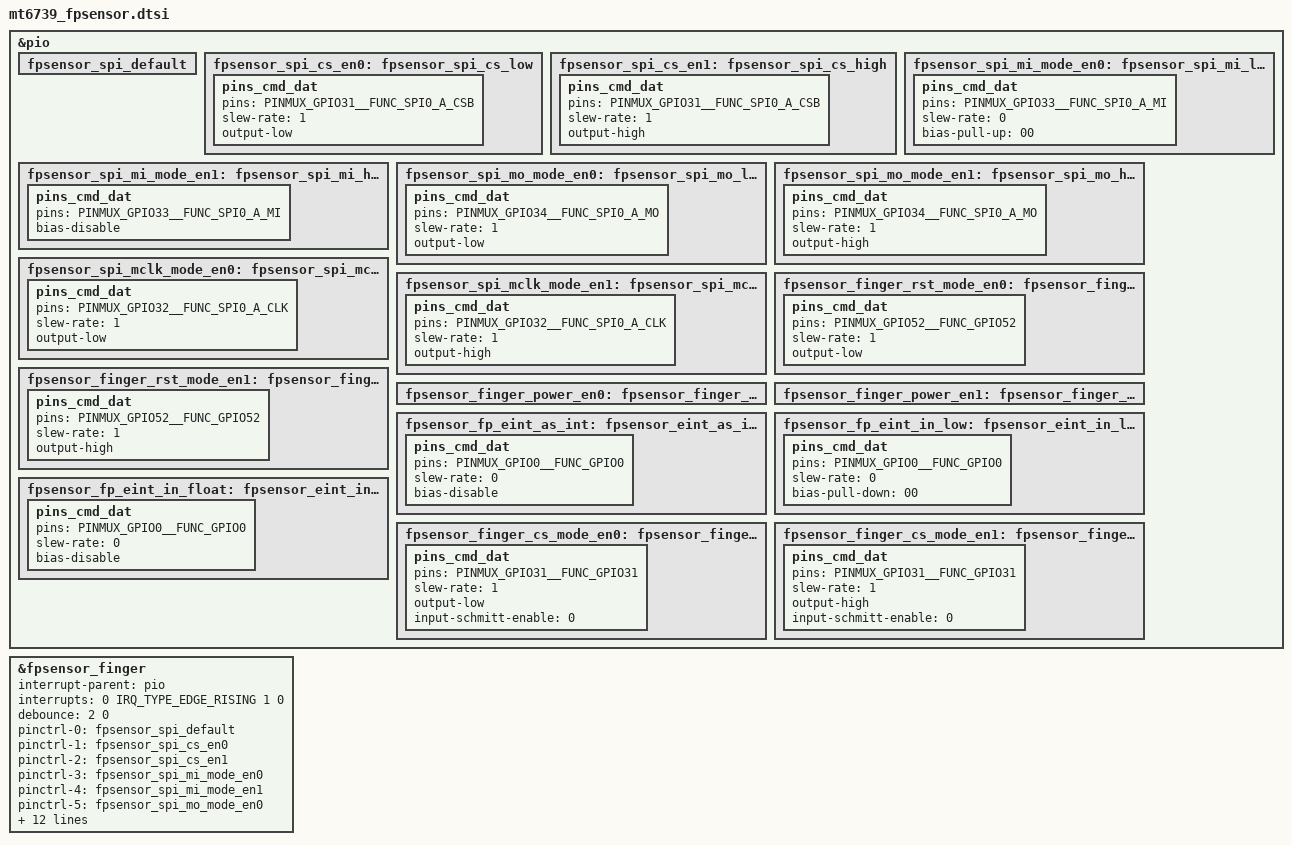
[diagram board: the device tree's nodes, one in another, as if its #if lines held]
#include <generated/autoconf.h>
//dts-v1

#ifdef CONFIG_MTK_DTBO_FEATURE
///plugin
#include <dt-bindings/clock/mt6739-clk.h>
#include <dt-bindings/mmc/mt6739-msdc.h>
#include <dt-bindings/pinctrl/mt6739-pinfunc.h>
#else
#include "mt6739.dts"
#endif

#include <dt-bindings/interrupt-controller/irq.h>
#include <dt-bindings/interrupt-controller/arm-gic.h>


/* FPSENSOR start */
&pio {

	fpsensor_spi_default: fpsensor_spi_default {
	};

	fpsensor_spi_cs_en0: fpsensor_spi_cs_low {
		pins_cmd_dat {
			pins = <PINMUX_GPIO31__FUNC_SPI0_A_CSB>;
			slew-rate = <1>;
			output-low;
		};
	};
	fpsensor_spi_cs_en1: fpsensor_spi_cs_high {
		pins_cmd_dat {
			pins = <PINMUX_GPIO31__FUNC_SPI0_A_CSB>;
			slew-rate = <1>;
			output-high;
		};
	};	
	fpsensor_spi_mi_mode_en0: fpsensor_spi_mi_low {
		pins_cmd_dat {
			pins = <PINMUX_GPIO33__FUNC_SPI0_A_MI>;
			slew-rate = <0>;
			bias-pull-up = <00>;
		};
	};
	fpsensor_spi_mi_mode_en1: fpsensor_spi_mi_high {
		pins_cmd_dat {
			pins = <PINMUX_GPIO33__FUNC_SPI0_A_MI>;
			bias-disable;
		};
	};	
	fpsensor_spi_mo_mode_en0: fpsensor_spi_mo_low {
		pins_cmd_dat {
			pins = <PINMUX_GPIO34__FUNC_SPI0_A_MO>;
			slew-rate = <1>;
			output-low;
		};
	};
	fpsensor_spi_mo_mode_en1: fpsensor_spi_mo_high {
		pins_cmd_dat {
			pins = <PINMUX_GPIO34__FUNC_SPI0_A_MO>;
			slew-rate = <1>;
			output-high;
		};
	};	
		fpsensor_spi_mclk_mode_en0: fpsensor_spi_mclk_low {
		pins_cmd_dat {
			pins = <PINMUX_GPIO32__FUNC_SPI0_A_CLK>;
			slew-rate = <1>;
			output-low;
		};
	};
	fpsensor_spi_mclk_mode_en1: fpsensor_spi_mclk_high {
		pins_cmd_dat {
			pins = <PINMUX_GPIO32__FUNC_SPI0_A_CLK>;
			slew-rate = <1>;
			output-high;
		};
	};	
	fpsensor_finger_rst_mode_en0: fpsensor_finger_rst_low {
		pins_cmd_dat {
			pins = <PINMUX_GPIO52__FUNC_GPIO52>;
			slew-rate = <1>;
			output-low; 
		};
	};
	fpsensor_finger_rst_mode_en1: fpsensor_finger_rst_high {
		pins_cmd_dat {
			pins = <PINMUX_GPIO52__FUNC_GPIO52>;
			slew-rate = <1>;
			output-high;
		};
	};	
	fpsensor_finger_power_en0: fpsensor_finger_power_low {
	
	};
	fpsensor_finger_power_en1: fpsensor_finger_power_high {
		
	};	
	fpsensor_fp_eint_as_int: fpsensor_eint_as_int {
		pins_cmd_dat {
			pins = <PINMUX_GPIO0__FUNC_GPIO0>;
			slew-rate = <0>;
			bias-disable;
		};
	};
	fpsensor_fp_eint_in_low: fpsensor_eint_in_low {
		pins_cmd_dat {
			pins = <PINMUX_GPIO0__FUNC_GPIO0>;
			slew-rate = <0>;
			bias-pull-down = <00>;
		};
	};
	fpsensor_fp_eint_in_float: fpsensor_eint_in_float {
		pins_cmd_dat {
			pins = <PINMUX_GPIO0__FUNC_GPIO0>;
			slew-rate = <0>;
			bias-disable;
		};
	};
	fpsensor_finger_cs_mode_en0: fpsensor_finger_cs_low {
		pins_cmd_dat {
			pins = <PINMUX_GPIO31__FUNC_GPIO31>;
			slew-rate = <1>;
			output-low;
			input-schmitt-enable = <0>;
		};
	};
	fpsensor_finger_cs_mode_en1: fpsensor_finger_cs_high {
		pins_cmd_dat {
			pins = <PINMUX_GPIO31__FUNC_GPIO31>;
			slew-rate = <1>;
			output-high;
			input-schmitt-enable = <0>;
		};
	};	
};

&fpsensor_finger {
	interrupt-parent = <&pio>;
	interrupts = <0 IRQ_TYPE_EDGE_RISING 1 0>;
	debounce = <2 0>;
	pinctrl-names = "fpsensor_spi_default", "fpsensor_spi_cs_low","fpsensor_spi_cs_high","fpsensor_spi_mi_low","fpsensor_spi_mi_high",
					"fpsensor_spi_mo_low","fpsensor_spi_mo_high","fpsensor_spi_mclk_low","fpsensor_spi_mclk_high",
					"fpsensor_finger_rst_low","fpsensor_finger_rst_high","fpsensor_finger_power_low","fpsensor_finger_power_high",
					"fpsensor_eint","fpsensor_eint_in_low","fpsensor_eint_in_float","fpsensor_finger_cs_low","fpsensor_finger_cs_high";
	pinctrl-0 = <&fpsensor_spi_default>;
	pinctrl-1 = <&fpsensor_spi_cs_en0>;
	pinctrl-2 = <&fpsensor_spi_cs_en1>;
	pinctrl-3 = <&fpsensor_spi_mi_mode_en0>;
	pinctrl-4 = <&fpsensor_spi_mi_mode_en1>;
	pinctrl-5 = <&fpsensor_spi_mo_mode_en0>;
	pinctrl-6 = <&fpsensor_spi_mo_mode_en1>;
	pinctrl-7 = <&fpsensor_spi_mclk_mode_en0>;
	pinctrl-8 = <&fpsensor_spi_mclk_mode_en1>;	
	pinctrl-9 = <&fpsensor_finger_rst_mode_en0>;
	pinctrl-10 = <&fpsensor_finger_rst_mode_en1>;
	pinctrl-11 = <&fpsensor_finger_power_en0>;
	pinctrl-12 = <&fpsensor_finger_power_en1>;	
	pinctrl-13 = <&fpsensor_fp_eint_as_int>;
	pinctrl-14 = <&fpsensor_fp_eint_in_low>;
	pinctrl-15 = <&fpsensor_fp_eint_in_float>;
	pinctrl-16 = <&fpsensor_finger_cs_mode_en0>;
	pinctrl-17 = <&fpsensor_finger_cs_mode_en1>;
	status = "okay";
};
/* FPSENSOR end */
